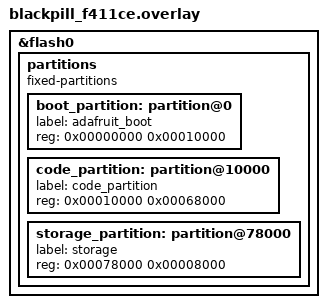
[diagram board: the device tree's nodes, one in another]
/*
 * Copyright (c) 2022 The ZMK Contributors
 *
 * SPDX-License-Identifier: MIT
 */

&flash0 {
	partitions {
		compatible = "fixed-partitions";
		#address-cells = <1>;
		#size-cells = <1>;

		boot_partition: partition@0 {
			label = "adafruit_boot";
			reg = <0x00000000 0x00010000>;
		};

		code_partition: partition@10000 {
			label = "code_partition";
			reg = <0x00010000 0x00068000>;
		};

		/*
		* The final 32 KiB is reserved for the application.
		* Storage partition will be used by FCB/LittleFS/NVS
		* if enabled.
		*/
		storage_partition: partition@78000 {
			label = "storage";
			reg = <0x00078000 0x00008000>;
		};
	};
};
